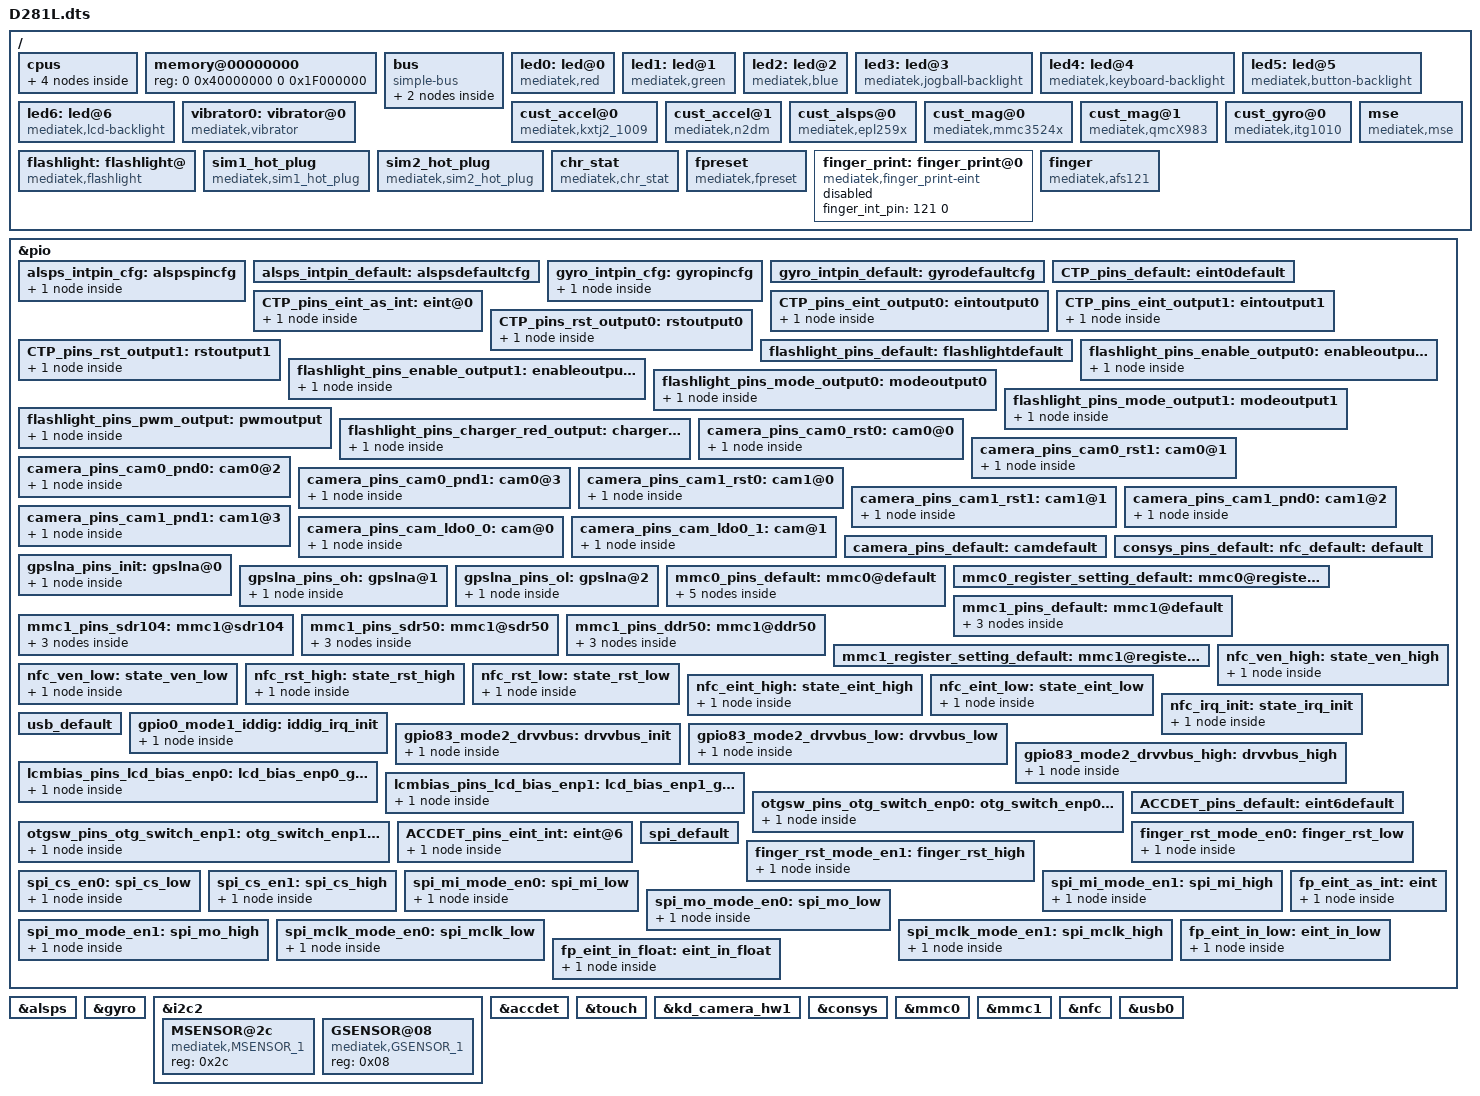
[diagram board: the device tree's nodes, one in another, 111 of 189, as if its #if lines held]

/dts-v1/;

#include "mt6735m.dtsi"
#include <dt-bindings/lcm/otm9608_qhd_dsi_cmd.dtsi>

/ {
	cpus {	#address-cells = <1>;
		#size-cells = <0>;

		cpu0: cpu@000 {
			device_type = "cpu";
			compatible = "arm,cortex-a53";
			reg = <0x000>;
			enable-method = "mt-boot";
			cpu-idle-states = <&cluster_sleep_0 &cluster_sleep_0 &cpu_sleep_0_0 &cpu_sleep_0_0>;
			cpu-release-addr = <0x0 0x40000200>;
			clock-frequency = <1100000000>;
		};

		cpu1: cpu@001 {
			device_type = "cpu";
			compatible = "arm,cortex-a53";
			reg = <0x001>;
			enable-method = "mt-boot";
			cpu-idle-states = <&cluster_sleep_0 &cluster_sleep_0 &cpu_sleep_0_0 &cpu_sleep_0_0>;
			cpu-release-addr = <0x0 0x40000200>;
			clock-frequency = <1100000000>;
		};

		cpu2: cpu@002 {
			device_type = "cpu";
			compatible = "arm,cortex-a53";
			reg = <0x002>;
			enable-method = "mt-boot";
			cpu-idle-states = <&cluster_sleep_0 &cluster_sleep_0 &cpu_sleep_0_0 &cpu_sleep_0_0>;
			cpu-release-addr = <0x0 0x40000200>;
			clock-frequency = <1100000000>;
		};

		cpu3: cpu@003 {
			device_type = "cpu";
			compatible = "arm,cortex-a53";
			reg = <0x003>;
			enable-method = "mt-boot";
			cpu-idle-states = <&cluster_sleep_0 &cluster_sleep_0 &cpu_sleep_0_0 &cpu_sleep_0_0>;
			cpu-release-addr = <0x0 0x40000200>;
			clock-frequency = <1100000000>;
		};
	};
	
	memory@00000000 {
		device_type = "memory";
		reg = <0 0x40000000 0 0x1F000000>;
	};

	bus {
		compatible = "simple-bus";
		#address-cells = <1>;
		#size-cells = <1>;
		ranges = <0 0 0 0xffffffff>;

		MALI@0x13040000 {
			compatible = "arm,malit720", "arm,mali-t72x", "arm,malit7xx", "arm,mali-midgard";
			reg = <0x13040000 0x4000>;
			interrupts = <0 212 0x8>, <0 211 0x8>, <0 210 0x8>;
			interrupt-names = "JOB", "MMU", "GPU";
			clock-frequency = <550000000>;
		};

		MTKFB@5e200000 {
			compatible = "mediatek,MTKFB";
			reg = <0x7F000000 0x1000000>;
		};

	};
//ranyanhao@wind-mobi.com 20160221 begin
	led0:led@0 {
		compatible = "mediatek,red";
		led_mode = <3>;
		data = <1>;
		pwm_config = <0 0 0 0 0>;
	};
	led1:led@1 {
		compatible = "mediatek,green";
		led_mode = <3>;
		data = <2>;
		pwm_config = <0 0 0 0 0>;
	};
//ranyanhao@wind-mobi.com 20160221 end
	led2:led@2 {
		compatible = "mediatek,blue";
		led_mode = <0>;
		data = <1>;
		pwm_config = <0 0 0 0 0>;
	};
	led3:led@3 {
		compatible = "mediatek,jogball-backlight";
		led_mode = <0>;
		data = <1>;
		pwm_config = <0 0 0 0 0>;
	};
	led4:led@4 {
		compatible = "mediatek,keyboard-backlight";
		led_mode = <0>;
		data = <1>;
		pwm_config = <0 0 0 0 0>;
	};
	led5:led@5 {
		compatible = "mediatek,button-backlight";
		led_mode = <0>;
		data = <1>;
		pwm_config = <0 0 0 0 0>;
	};
	led6:led@6 {
		compatible = "mediatek,lcd-backlight";
		led_mode = <5>;
		data = <1>;
		pwm_config = <0 0 0 0 0>;
	};
	vibrator0:vibrator@0 {
		compatible = "mediatek,vibrator";
		vib_timer = <25>;
		vib_limit = <9>;
//ranyanhao@wind-mobi.com 20160120 begin
		vib_vol= <6>;
//ranyanhao@wind-mobi.com 20160120 end
	};
 /* sensor standardization */
		cust_accel@0 {
/*huangzhaosong@wind-mobi.com 20151231 s---*/
		compatible = "mediatek,kxtj2_1009";
		i2c_num	= <2>;
		i2c_addr = <0x0e 0 0 0>;
		direction = <5>;
		power_id = <0xffff>;
		power_vol = <0>;
		firlen = <0>;
		is_batch_supported = <0>;
/*huangzhaosong@wind-mobi.com 20151231 e---*/
		};
/*hebiao@wind-mobi.com  20151230 begin*/
		cust_accel@1 {
		compatible = "mediatek,n2dm";
		i2c_num	= <2>;
		i2c_addr = <0x08 0 0 0>;
		direction = <5>;
		power_id = <0xffff>;
		power_vol = <0>;
		firlen = <6>;
		is_batch_supported = <0>;
		};
/*hebiao@wind-mobi.com  20151230 end*/

		cust_alsps@0 {
/*ranyanhao@wind-mobi.com  20151230 begin*/
		compatible = "mediatek,epl259x";
		i2c_num	= <2>;
		i2c_addr = <0x49 0 0 0>;
		polling_mode_ps = <0>;
		polling_mode_als = <1>;
		power_id = <0xffff>;
		power_vol = <0>;
		als_level = <30 160 260 605 1010 1380 1760 2100 2600 4000 5500 7000 9000 15000 20000>; /*modified by hebiao 2016413*/
		als_value = <0 50 100 260 400 520 700 850 1050 1550 3000 5000 7000 9000 20000 20000>;/*modified by hebiao 2016413*/
		ps_threshold_high		=  <800>;
		ps_threshold_low		=  <500>;
		is_batch_supported_ps	= <0>;
		is_batch_supported_als	= <0>;
/*ranyanhao@wind-mobi.com  20151230 end*/
		};
		
/*ranyanhao@wind-mobi.com  20160120 begin*/
		cust_mag@0 {
		compatible				= "mediatek,mmc3524x";
		i2c_num					= <2>;
		i2c_addr				= <0x30 0 0 0>;
		direction				= <7>;
		power_id				= <0xffff>;
		power_vol				= <0>;
		is_batch_supported			= <0>;
		};
/*ranyanhao@wind-mobi.com  20160120 end*/

/*hebiao@wind-mobi.com  20160324 begin*/
cust_mag@1 {
		compatible				= "mediatek,qmcX983";
		i2c_num					= <2>;
		i2c_addr				= <0x2c 0 0 0>;
		/*modified by lifengxiang@wind-mobi.com 20160628 begin*/
		direction				= <4>;
		/*modified by lifengxiang@wind-mobi.com 20160628 end*/
		power_id				= <0xffff>;
		power_vol				= <0>;
		is_batch_supported			= <0>;
		}; 
/*hebiao@wind-mobi.com  20160324 end*/

		cust_gyro@0 {
		compatible				= "mediatek,itg1010";
		i2c_num					= <2>;
		i2c_addr				= <0x68 0 0 0>;
		direction				= <3>;
		power_id				= <0xffff>;
		power_vol				= <0>;
		firlen					= <0>;
		is_batch_supported			= <0>;
		};

/*hebiao@wind-mobi.com 20160219 begin*/
		flashlight: flashlight@ {
	 			compatible = "mediatek,flashlight";
		};
/*hebiao@wind-mobi.com 20160219 end*/
		
/* ranyanhao@wind-mobi.com 20160121 begin */
		sim1_hot_plug: sim1_hot_plug {
			compatible = "mediatek,sim1_hot_plug";
		};
		
		sim2_hot_plug: sim2_hot_plug {
			compatible = "mediatek,sim2_hot_plug";
		};
		
		mse: mse {
			compatible = "mediatek,mse";
		};
		
		chr_stat: chr_stat {
			compatible = "mediatek,chr_stat";
		};
/* ranyanhao@wind-mobi.com 20160121 end */

/*liukangping@wind-mobi.com 20160421 begin  */
fpreset: fpreset{
    compatible = "mediatek,fpreset";
	pinctrl-names =  "spi_default", "finger_rst_low", "finger_rst_high";
	pinctrl-0 = <&spi_default>;
	pinctrl-1 = <&finger_rst_mode_en0>;
	pinctrl-2 = <&finger_rst_mode_en1>;
	status = "okay";
};
/*liukangping@wind-mobi.com 20160421 end  */

/*****zhenglihong@wind-mobi.com 20160430 begin*********/		
/*ranyanhao@wind-mobi.com 20160229 begin*/
		finger_print: finger_print@0 {
			compatible = "mediatek,finger_print-eint";
		/*dingyisheng@wind-mobi.com 20170317 begin  */
			finger_int_pin = <121 0>;
		/*dingyisheng@wind-mobi.com 20170317 end  */
			status = "disabled";
		};
		finger:finger {
			compatible = "mediatek,afs121";
				pinctrl-names = "spi_default","spi_cs_low","spi_cs_high","spi_mi_low","spi_mi_high",
					"spi_mo_low","spi_mo_high","spi_mclk_low","spi_mclk_high",
					"finger_rst_low","finger_rst_high",
					"eint","eint_in_low","eint_in_float";
			pinctrl-0 = <&spi_default>;
			pinctrl-1 = <&spi_cs_en0>;
			pinctrl-2 = <&spi_cs_en1>;
			pinctrl-3 = <&spi_mi_mode_en0>;
			pinctrl-4 = <&spi_mi_mode_en1>;
			pinctrl-5 = <&spi_mo_mode_en0>;
			pinctrl-6 = <&spi_mo_mode_en1>;
			pinctrl-7 = <&spi_mclk_mode_en0>;
			pinctrl-8 = <&spi_mclk_mode_en1>;
			pinctrl-9 = <&finger_rst_mode_en0>;
			pinctrl-10 = <&finger_rst_mode_en1>;
			pinctrl-11 = <&fp_eint_as_int>;
			pinctrl-12 = <&fp_eint_in_low>;
			pinctrl-13 = <&fp_eint_in_float>;
			status = "okay";
		};
/*ranyanhao@wind-mobi.com 20160229 end*/
};
/******zhenglihong@wind-mobi.com 20160430 end***********************/

/* sensor gpio standization */
&pio {
	alsps_intpin_cfg: alspspincfg {

	    pins_cmd_dat {
		/*ranyanhao@wind-mobi.com 20160120 begin*/
			pins = <PINMUX_GPIO77__FUNC_GPIO77>;
		/*ranyanhao@wind-mobi.com 20160120 end*/
			slew-rate = <0>;
			bias-pull-up = <00>;
		};
	};

	alsps_intpin_default: alspsdefaultcfg {

	};

	gyro_intpin_cfg: gyropincfg {

	    pins_cmd_dat {
			pins = <PINMUX_GPIO67__FUNC_GPIO67>;
			slew-rate = <0>;
			bias-pull-down = <00>;
		};
	};

	gyro_intpin_default: gyrodefaultcfg {

	};
};
&alsps {
	pinctrl-names = "pin_default", "pin_cfg";
	pinctrl-0 = <&alsps_intpin_default>;
	pinctrl-1 = <&alsps_intpin_cfg>;
	status = "okay";

};

&gyro {
	pinctrl-names = "pin_default", "pin_cfg";
	pinctrl-0 = <&gyro_intpin_default>;
	pinctrl-1 = <&gyro_intpin_cfg>;
	status = "okay";

};
/* sensor end */

/* i2c reuse begin */
/* hebiao@wind-mobi.com 20160315 begin */
&i2c2 {
	MSENSOR@2c {
		compatible = "mediatek,MSENSOR_1";
		reg = <0x2c>;
	};
	};

&i2c2 {
	GSENSOR@08 {
		compatible = "mediatek,GSENSOR_1";
		reg = <0x08>;
	};
	};
/* hebiao@wind-mobi.com 20160315 end */
/* i2c reuse end */

/* ranyanhao@wind-mobi.com 20160120 begin */
&accdet {
	accdet-mic-vol = <7>;
	headset-mode-setting = <0x500 0x200 1 0x1F0 0x800 0x800 0x20>;
	accdet-plugout-debounce = <20>;
	/*1:ACC mode, 2:low cost without in bias, 6:low cost with in bias*/
	accdet-mic-mode = <1>;
	/*0--MD_MAX--UP_MAX--DW_MAX*/
	headset-three-key-threshold = <0 80 220 500>;
	/*0--MD_MAX--VOICE_MAX--UP_MAX--DW_MAX*/
	headset-four-key-threshold = <0 58 121 192 450>;
	pinctrl-names = "default", "state_eint_as_int";
	pinctrl-0 = <&ACCDET_pins_default>;
	pinctrl-1 = <&ACCDET_pins_eint_int>;
	status = "okay";
};
/* ranyanhao@wind-mobi.com 20160120 end */
&touch {
	tpd-resolution = <720 1280>;
	use-tpd-button = <0>;
	tpd-key-num = <3>;
	tpd-key-local= <139 172 158 0>;
	tpd-key-dim-local = <90 883 100 40 230 883 100 40 370 883 100 40 0 0 0 0>;
	tpd-max-touch-num = <5>;
	tpd-filter-enable = <1>;
	tpd-filter-pixel-density = <124>;
	tpd-filter-custom-prameters = <0 0 0 0 0 0 0 0 0 0 0 0>;
	tpd-filter-custom-speed = <0 0 0>;
	pinctrl-names = "default", "state_eint_as_int", "state_eint_output0", "state_eint_output1",
		"state_rst_output0", "state_rst_output1";
	pinctrl-0 = <&CTP_pins_default>;
	pinctrl-1 = <&CTP_pins_eint_as_int>;
	pinctrl-2 = <&CTP_pins_eint_output0>;
	pinctrl-3 = <&CTP_pins_eint_output1>;
	pinctrl-4 = <&CTP_pins_rst_output0>;
	pinctrl-5 = <&CTP_pins_rst_output1>;
	status = "okay";
};
&pio {
	CTP_pins_default: eint0default {
	};
	CTP_pins_eint_as_int: eint@0 {
		pins_cmd_dat {
			pins = <PINMUX_GPIO10__FUNC_GPIO10>;
			slew-rate = <0>;
			bias-pull-up = <00>;  /*pull up int  modified by hebiao*/
			/*bias-disable;*/
		};
	};
	CTP_pins_eint_output0: eintoutput0 {
		pins_cmd_dat {
			pins = <PINMUX_GPIO10__FUNC_GPIO10>;
			slew-rate = <1>;
			output-low;
		};
	};
	CTP_pins_eint_output1: eintoutput1 {
		pins_cmd_dat {
			pins = <PINMUX_GPIO10__FUNC_GPIO10>;
			slew-rate = <1>;
			output-high;
		};
	};
	CTP_pins_rst_output0: rstoutput0 {
		pins_cmd_dat {
			pins = <PINMUX_GPIO62__FUNC_GPIO62>;
			slew-rate = <1>;
			output-low;
		};
	};
	CTP_pins_rst_output1: rstoutput1 {
		pins_cmd_dat {
			pins = <PINMUX_GPIO62__FUNC_GPIO62>;
			slew-rate = <1>;
			output-high;
		};
	};
};
/* TOUCH end */

/* hebiao@wind-mobi.com 20160219 begin */
&flashlight {
	pinctrl-names =  "default", "state_enable_output0", "state_enable_output1",
		"state_mode_output0", "state_mode_output1", "state_pwm_output", "charger_red_GPIO_output";
	pinctrl-0 = <&flashlight_pins_default>;
	pinctrl-1 = <&flashlight_pins_enable_output0>;
	pinctrl-2 = <&flashlight_pins_enable_output1>;
	pinctrl-3 = <&flashlight_pins_mode_output0>;
	pinctrl-4 = <&flashlight_pins_mode_output1>;
	pinctrl-5 = <&flashlight_pins_pwm_output>;
	pinctrl-6 = <&flashlight_pins_charger_red_output>;
	status = "okay";
};

&pio {
	flashlight_pins_default: flashlightdefault {
	};
	flashlight_pins_enable_output0: enableoutput0 {
		pins_cmd_dat {
			pins = <PINMUX_GPIO42__FUNC_GPIO42>;
			slew-rate = <1>;
			output-low;
		};
	};
	flashlight_pins_enable_output1: enableoutput1 {
		pins_cmd_dat {
			pins = <PINMUX_GPIO42__FUNC_GPIO42>;
			slew-rate = <1>;
			output-high;
		};
	};
	flashlight_pins_mode_output0: modeoutput0 {
		pins_cmd_dat {
			pins = <PINMUX_GPIO1__FUNC_GPIO1>;
			slew-rate = <1>;
			output-low;
		};
	};
	flashlight_pins_mode_output1: modeoutput1 {
		pins_cmd_dat {
			pins = <PINMUX_GPIO1__FUNC_GPIO1>;
			slew-rate = <1>;
			output-high;	
		};
	};
	flashlight_pins_pwm_output: pwmoutput {
		pins_cmd_dat {
			pins = <PINMUX_GPIO1__FUNC_PWM2>;
			slew-rate = <1>;
		};
	};
	flashlight_pins_charger_red_output: charger_red_GPIO_output { 
		pins_cmd_dat {
			pins = <PINMUX_GPIO57__FUNC_GPIO57>;
			slew-rate = <1>;
			output-high;
		};
	};
};
/* hebiao@wind-mobi.com 20160219 end */

/* ranyanhao@wind-mobi.com 20160121 begin */
&sim1_hot_plug {
	status = "okay";
};

&sim2_hot_plug {
	status = "okay";
};

&mse {
	status = "okay";
};

&chr_stat {
	status = "okay";
};
/* ranyanhao@wind-mobi.com 20160121 end */

/* CAMERA GPIO standardization */
&pio {
	camera_pins_cam0_rst0: cam0@0 {
	    pins_cmd_dat {
			pins = <PINMUX_GPIO44__FUNC_GPIO44>;/*GPIO_CAMERA_CMRST_PIN*/
			slew-rate = <1>; /*direction 0:in, 1:out*/
			output-low;/*direction out used only. output_low or high*/
		};
	};
	camera_pins_cam0_rst1: cam0@1 {
	    pins_cmd_dat {
			pins = <PINMUX_GPIO44__FUNC_GPIO44>;/*GPIO_CAMERA_CMRST_PIN*/
			slew-rate = <1>;
			output-high;
		};
	};
	camera_pins_cam0_pnd0: cam0@2 {
	    pins_cmd_dat {
			pins = <PINMUX_GPIO7__FUNC_GPIO7>;/*GPIO_CAMERA_CMPDN_PIN*/
			slew-rate = <1>;
			output-low;
		};
	};
	camera_pins_cam0_pnd1: cam0@3 {
	    pins_cmd_dat {
			pins = <PINMUX_GPIO7__FUNC_GPIO7>;/*GPIO_CAMERA_CMPDN_PIN*/
			slew-rate = <1>;
			output-high;
		};
	};
	camera_pins_cam1_rst0: cam1@0 {
	    pins_cmd_dat {
			pins = <PINMUX_GPIO11__FUNC_GPIO11>;/*GPIO_CAMERA_CMRST1_PIN*/
			slew-rate = <1>; /*direction 0:in, 1:out*/
			output-low;/*direction out used only. output_low or high*/
		};
	};
	camera_pins_cam1_rst1: cam1@1 {
	    pins_cmd_dat {
			pins = <PINMUX_GPIO11__FUNC_GPIO11>;/*GPIO_CAMERA_CMRST1_PIN*/
			slew-rate = <1>;
			output-high;
		};
	};
	camera_pins_cam1_pnd0: cam1@2 {
	    pins_cmd_dat {
			pins = <PINMUX_GPIO12__FUNC_GPIO12>;/*GPIO_CAMERA_CMPDN1_PIN*/
			slew-rate = <1>;
			output-low;
		};
	};
	camera_pins_cam1_pnd1: cam1@3 {
	    pins_cmd_dat {
			pins = <PINMUX_GPIO12__FUNC_GPIO12>;/*GPIO_CAMERA_CMPDN1_PIN*/
			slew-rate = <1>;
			output-high;
		};
	};
	camera_pins_cam_ldo0_0: cam@0 {
	    pins_cmd_dat {
			pins = <PINMUX_GPIO68__FUNC_GPIO68>;/*GPIO_SPI_MOSI_PIN*/
			slew-rate = <1>;
			output-low;
		};
	};
	camera_pins_cam_ldo0_1: cam@1 {
		pins_cmd_dat {
			pins = <PINMUX_GPIO68__FUNC_GPIO68>;/*GPIO_SPI_MOSI_PIN*/
			slew-rate = <1>;
			output-high;
		};
	};
	camera_pins_default: camdefault {
	};

};

&kd_camera_hw1 {
	pinctrl-names = "default", "cam0_rst0", "cam0_rst1", "cam0_pnd0", "cam0_pnd1",
			"cam1_rst0", "cam1_rst1", "cam1_pnd0", "cam1_pnd1","cam_ldo0_0", "cam_ldo0_1";
	pinctrl-0 = <&camera_pins_default>;
	pinctrl-1 = <&camera_pins_cam0_rst0>;
	pinctrl-2 = <&camera_pins_cam0_rst1>;
	pinctrl-3 = <&camera_pins_cam0_pnd0>;
	pinctrl-4 = <&camera_pins_cam0_pnd1>;
	pinctrl-5 = <&camera_pins_cam1_rst0>;
	pinctrl-6 = <&camera_pins_cam1_rst1>;
	pinctrl-7 = <&camera_pins_cam1_pnd0>;
	pinctrl-8 = <&camera_pins_cam1_pnd1>;
	pinctrl-9 = <&camera_pins_cam_ldo0_0>;
	pinctrl-10 = <&camera_pins_cam_ldo0_1>;
	status = "okay";

};
/* CAMERA GPIO end */

/* CONSYS GPIO standardization */
&pio {
	consys_pins_default: default {

	};

	gpslna_pins_init: gpslna@0 {

	    pins_cmd_dat {
			pins = <PINMUX_GPIO79__FUNC_GPIO79>;
			slew-rate = <0>;
			bias-disable;
			output-low;
		};
	};

	gpslna_pins_oh: gpslna@1 {

	    pins_cmd_dat {
			pins = <PINMUX_GPIO79__FUNC_GPIO79>;
			slew-rate = <1>;
			output-high;
		};
	};

	gpslna_pins_ol: gpslna@2 {

	    pins_cmd_dat {
			pins = <PINMUX_GPIO79__FUNC_GPIO79>;
			slew-rate = <1>;
			output-low;
		};
	};

};

&consys {
	pinctrl-names = "default", "gps_lna_state_init", "gps_lna_state_oh", "gps_lna_state_ol";
	pinctrl-0 = <&consys_pins_default>;
	pinctrl-1 = <&gpslna_pins_init>;
	pinctrl-2 = <&gpslna_pins_oh>;
	pinctrl-3 = <&gpslna_pins_ol>;
	status = "okay";

};
/* CONSYS end */

/* mmc start */
&mmc0 {
		clk_src = /bits/ 8 <MSDC50_CLKSRC_400MHZ>;
		bus-width = <8>;
		max-frequency = <200000000>;
		cap-mmc-highspeed;
		msdc-sys-suspend;
		mmc-ddr-1_8v;
		mmc-hs200-1_8v;
		mmc-hs400-1_8v;
		non-removable;
		pinctl = <&mmc0_pins_default>;
		register_setting = <&mmc0_register_setting_default>;
		host_function = /bits/ 8 <MSDC_EMMC>;
		bootable;
		status = "okay";
};

&mmc1 {
		clk_src = /bits/ 8 <MSDC30_CLKSRC_200MHZ>;
		bus-width = <4>;
		max-frequency = <200000000>;
		msdc-sys-suspend;
		cap-sd-highspeed;
		sd-uhs-sdr12;
		sd-uhs-sdr25;
		sd-uhs-sdr50;
		sd-uhs-sdr104;
		sd-uhs-ddr50;
		pinctl = <&mmc1_pins_default>;
		pinctl_sdr104 = <&mmc1_pins_sdr104>;
		pinctl_sdr50 = <&mmc1_pins_sdr50>;
		pinctl_ddr50 = <&mmc1_pins_ddr50>;
		register_setting = <&mmc1_register_setting_default>;
		host_function = /bits/ 8 <MSDC_SD>;
		cd_level = /bits/ 8 <MSDC_CD_LOW>;
		cd-gpios = <&pio 5 0>;
		status = "okay";
};

&pio {
	mmc0_pins_default: mmc0@default {
			pins_cmd {
				drive-strength = /bits/ 8 <2>;
			};
			pins_dat {
				drive-strength = /bits/ 8 <2>;
			};
			pins_clk {
				drive-strength = /bits/ 8 <2>;
			};
			pins_rst {
				drive-strength = /bits/ 8 <2>;
			};
			pins_ds {
				drive-strength = /bits/ 8 <2>;
			};
	};

	mmc0_register_setting_default: mmc0@register_default {
		dat0rddly      = /bits/ 8 <0>;
		dat1rddly      = /bits/ 8 <0>;
		dat2rddly      = /bits/ 8 <0>;
		dat3rddly      = /bits/ 8 <0>;
		dat4rddly      = /bits/ 8 <0>;
		dat5rddly      = /bits/ 8 <0>;
		dat6rddly      = /bits/ 8 <0>;
		dat7rddly      = /bits/ 8 <0>;
		datwrddly      = /bits/ 8 <0>;
		cmdrrddly      = /bits/ 8 <0>;
		cmdrddly       = /bits/ 8 <0>;
		cmd_edge = /bits/ 8 <MSDC_SMPL_FALLING>;
		rdata_edge = /bits/ 8 <MSDC_SMPL_FALLING>;
		wdata_edge = /bits/ 8 <MSDC_SMPL_FALLING>;

		ett-hs200-cells = <12>;
		ett-hs200-default = <OFFSET_MSDC_PATCH_BIT0	MSDC_PB0_INT_DAT_LATCH_CK_SEL 0x0
			OFFSET_MSDC_PATCH_BIT0	MSDC_PB0_CKGEN_MSDC_DLY_SEL   0x0
			OFFSET_MSDC_PATCH_BIT1	MSDC_PB1_CMD_RSP_TA_CNTR      0x1
			OFFSET_MSDC_IOCON		MSDC_IOCON_RSPL               0x0
			OFFSET_MSDC_PAD_TUNE0	MSDC_PAD_TUNE0_CMDRDLY        0x7
			OFFSET_MSDC_PAD_TUNE0	MSDC_PAD_TUNE0_CMDRRDLY       0xb
			OFFSET_MSDC_PATCH_BIT1		MSDC_PB1_WRDAT_CRCS_TA_CNTR   0x1
			OFFSET_MSDC_PAD_TUNE0	MSDC_PAD_TUNE0_DATWRDLY       0xb
			OFFSET_MSDC_IOCON			MSDC_IOCON_W_D0SPL            0x0
			OFFSET_MSDC_DAT_RDDLY0		MSDC_DAT_RDDLY0_D0            0x7
			OFFSET_MSDC_PAD_TUNE0	MSDC_PAD_TUNE0_DATRRDLY       0x9
			OFFSET_MSDC_IOCON		MSDC_IOCON_R_D_SMPL           0x0>;

		ett-hs400-cells = <8>;
		ett-hs400-default = <OFFSET_MSDC_PATCH_BIT0	MSDC_PB0_INT_DAT_LATCH_CK_SEL	0x0
			OFFSET_MSDC_PATCH_BIT0		MSDC_PB0_CKGEN_MSDC_DLY_SEL		0x0
			OFFSET_EMMC50_PAD_DS_TUNE	MSDC_EMMC50_PAD_DS_TUNE_DLY1	0x2
			OFFSET_EMMC50_PAD_DS_TUNE	MSDC_EMMC50_PAD_DS_TUNE_DLY3	0x10
			OFFSET_MSDC_PATCH_BIT1			MSDC_PB1_CMD_RSP_TA_CNTR	0x1
			OFFSET_MSDC_IOCON		MSDC_IOCON_RSPL				0x0
			OFFSET_MSDC_PAD_TUNE0			MSDC_PAD_TUNE0_CMDRDLY		0x6
			OFFSET_MSDC_PAD_TUNE0		MSDC_PAD_TUNE0_CMDRRDLY		0x6>;
	};

	mmc1_pins_default: mmc1@default {
			pins_cmd {
				drive-strength = /bits/ 8 <3>;
			};
			pins_dat {
				drive-strength = /bits/ 8 <3>;
			};
			pins_clk {
				drive-strength = /bits/ 8 <3>;
			};
	};

	mmc1_pins_sdr104: mmc1@sdr104 {
			pins_cmd {
				drive-strength = /bits/ 8 <2>;
			};
			pins_dat {
				drive-strength = /bits/ 8 <2>;
			};
			pins_clk {
				drive-strength = /bits/ 8 <3>;
			};
	};

	mmc1_pins_sdr50: mmc1@sdr50 {
			pins_cmd {
				drive-strength = /bits/ 8 <2>;
			};
			pins_dat {
				drive-strength = /bits/ 8 <2>;
			};
			pins_clk {
				drive-strength = /bits/ 8 <3>;
			};
	};

	mmc1_pins_ddr50: mmc1@ddr50 {
			pins_cmd {
				drive-strength = /bits/ 8 <2>;
			};
			pins_dat {
				drive-strength = /bits/ 8 <2>;
			};
			pins_clk {
				drive-strength = /bits/ 8 <3>;
			};
	};

	mmc1_register_setting_default: mmc1@register_default {
				dat0rddly      = /bits/ 8 <0>;
				dat1rddly      = /bits/ 8 <0>;
				dat2rddly      = /bits/ 8 <0>;
				dat3rddly      = /bits/ 8 <0>;
				datwrddly      = /bits/ 8 <0>;
				cmdrrddly      = /bits/ 8 <0>;
				cmdrddly       = /bits/ 8 <0>;
				cmd_edge = /bits/ 8 <MSDC_SMPL_FALLING>;
				rdata_edge = /bits/ 8 <MSDC_SMPL_FALLING>;
				wdata_edge = /bits/ 8 <MSDC_SMPL_FALLING>;
	};
};
/* mmc end */

/* NFC GPIO standardization */
&pio {
	nfc_default: default {

	};

	nfc_ven_high: state_ven_high {
		pins_cmd_dat {
			pins = <PINMUX_GPIO4__FUNC_GPIO4>;
			slew-rate = <1>;
			output-high;
		};
	};

	nfc_ven_low: state_ven_low {
		pins_cmd_dat {
			pins = <PINMUX_GPIO4__FUNC_GPIO4>;
			slew-rate = <1>;
			output-low;
		};
	};

	nfc_rst_high: state_rst_high {
		pins_cmd_dat {
			pins = <PINMUX_GPIO3__FUNC_GPIO3>;
			slew-rate = <1>;
			output-high;
		};
	};

	nfc_rst_low: state_rst_low {
		pins_cmd_dat {
			pins = <PINMUX_GPIO3__FUNC_GPIO3>;
			slew-rate = <1>;
			output-low;
		};
	};

	nfc_eint_high: state_eint_high {
		pins_cmd_dat {
			pins = <PINMUX_GPIO1__FUNC_GPIO1>;
			slew-rate = <1>;
			output-high;
		};
	};

	nfc_eint_low: state_eint_low {
		pins_cmd_dat {
			pins = <PINMUX_GPIO1__FUNC_GPIO1>;
			slew-rate = <1>;
			output-low;
		};
	};

	nfc_irq_init: state_irq_init {
		pins_cmd_dat {
			pins = <PINMUX_GPIO2__FUNC_GPIO2>;
			slew-rate = <0>;
			bias-pull-down = <00>;
		};
	};
};

&nfc {
	pinctrl-names = "default", "ven_high", "ven_low", "rst_high", "rst_low", "eint_high", "eint_low", "irq_init";
	pinctrl-0 = <&nfc_default>;
	pinctrl-1 = <&nfc_ven_high>;
	pinctrl-2 = <&nfc_ven_low>;
	pinctrl-3 = <&nfc_rst_high>;
	pinctrl-4 = <&nfc_rst_low>;
	pinctrl-5 = <&nfc_eint_high>;
	pinctrl-6 = <&nfc_eint_low>;
	pinctrl-7 = <&nfc_irq_init>;
	status = "okay";
};
/* NFC end */

/* USB GPIO Kernal Standardization start */
&pio {
	usb_default: usb_default {
	};

	gpio0_mode1_iddig: iddig_irq_init {
		pins_cmd_dat {
			pins = <PINMUX_GPIO0__FUNC_IDDIG>;
			slew-rate = <0>;
			bias-pull-up = <00>;
		};
	};

	gpio83_mode2_drvvbus: drvvbus_init {
		pins_cmd_dat {
			pins = <PINMUX_GPIO83__FUNC_GPIO83>;
			slew-rate = <1>;
			bias-pull-down = <00>;
		};
	};

	gpio83_mode2_drvvbus_low: drvvbus_low {
		pins_cmd_dat {
			pins = <PINMUX_GPIO83__FUNC_GPIO83>;
			slew-rate = <1>;
			output-low;
			bias-pull-down = <00>;
		};
	};

	gpio83_mode2_drvvbus_high: drvvbus_high {
		pins_cmd_dat {
			pins = <PINMUX_GPIO83__FUNC_GPIO83>;
			slew-rate = <1>;
			output-high;
			bias-pull-down = <00>;
		};
	};
};

&usb0 {
	iddig_gpio = <0 1>;
	pinctrl-names = "usb_default", "iddig_irq_init", "drvvbus_init", "drvvbus_low", "drvvbus_high";
	pinctrl-0 = <&usb_default>;
	pinctrl-1 = <&gpio0_mode1_iddig>;
	pinctrl-2 = <&gpio83_mode2_drvvbus>;
	pinctrl-3 = <&gpio83_mode2_drvvbus_low>;
	pinctrl-4 = <&gpio83_mode2_drvvbus_high>;
	status = "okay";
};
/* USB GPIO Kernal Standardization end */

/* zhaozhensen@wind-mobi.com 20160423 begin*/
&pio {

	lcmbias_pins_default: default {
	};

	lcmbias_pins_lcd_bias_enp0: lcd_bias_enp0_gpio {
		pins_cmd_dat {
			pins = <PINMUX_GPIO119__FUNC_GPIO119>;
			slew-rate = <1>;
			output-low;
		};
	};

	lcmbias_pins_lcd_bias_enp1: lcd_bias_enp1_gpio {
		pins_cmd_dat {
			pins = <PINMUX_GPIO119__FUNC_GPIO119>;
			slew-rate = <1>;
			output-high;
		};
	};

};

/* zhaozhensen@wind-mobi.com 20160423 end*/

/* yutao@wind-mobi.com 20160601 begin*/
&pio {

	otgsw_pins_default: default {
	};

	otgsw_pins_otg_switch_enp0: otg_switch_enp0_gpio {
		pins_cmd_dat {
			pins = <PINMUX_GPIO3__FUNC_GPIO3>;
			slew-rate = <1>;
			output-low;
		};
	};

	otgsw_pins_otg_switch_enp1: otg_switch_enp1_gpio {
		pins_cmd_dat {
			pins = <PINMUX_GPIO3__FUNC_GPIO3>;
			slew-rate = <1>;
			output-high;
		};
	};

};

/* yutao@wind-mobi.com 20160601 end*/

/* ranyanhao@wind-mobi.com 20160120 begin */
/* ACCDET GPIO Standardization ACC mode use */
&pio {
	ACCDET_pins_default:eint6default {
	};
	ACCDET_pins_eint_int:eint@6 {
		pins_cmd_dat {
			pins = <PINMUX_GPIO6__FUNC_GPIO6>;
			slew-rate = <0>;
			bias-disable;
		};
	};
};
/* ACCDET END */
/* ranyanhao@wind-mobi.com 20160120 end */

/*liukangping@wind-mobi.com 20160421 begin */		
&pio {
	spi_default: spi_default {
	};
	
	finger_rst_mode_en0: finger_rst_low {
		pins_cmd_dat {
			pins = <PINMUX_GPIO122__FUNC_GPIO122>;
			slew-rate = <1>;
			output-low;
		};
	};
	finger_rst_mode_en1: finger_rst_high {
		pins_cmd_dat {
			pins = <PINMUX_GPIO122__FUNC_GPIO122>;
			slew-rate = <1>;
			output-high;
		};
	};	
	
};
/*liukangping@wind-mobi.com 20160421 end */
/* ranyanhao@wind-mobi.com 20160120 begin */
&pio {
	spi_default: spi_default {
	};

	spi_cs_en0: spi_cs_low {
		pins_cmd_dat {
			pins = <PINMUX_GPIO65__FUNC_SPI_CSA>;
			slew-rate = <1>;
			output-low;
		};
	};
	spi_cs_en1: spi_cs_high {
		pins_cmd_dat {
			pins = <PINMUX_GPIO65__FUNC_SPI_CSA>;
			slew-rate = <1>;
			output-high;
		};
	};	
	spi_mi_mode_en0: spi_mi_low {
		pins_cmd_dat {
			pins = <PINMUX_GPIO67__FUNC_SPI_MIA>;
			slew-rate = <0>;
			bias-pull-up = <00>;
		};
	};
	spi_mi_mode_en1: spi_mi_high {
		pins_cmd_dat {
			pins = <PINMUX_GPIO67__FUNC_SPI_MIA>;
			bias-disable;
		};
	};	
	spi_mo_mode_en0: spi_mo_low {
		pins_cmd_dat {
			pins = <PINMUX_GPIO68__FUNC_SPI_MOA>;
			slew-rate = <1>;
			output-low;
		};
	};
	spi_mo_mode_en1: spi_mo_high {
		pins_cmd_dat {
			pins = <PINMUX_GPIO68__FUNC_SPI_MOA>;
			slew-rate = <1>;
			output-high;
		};
	};	
		spi_mclk_mode_en0: spi_mclk_low {
		pins_cmd_dat {
			pins = <PINMUX_GPIO66__FUNC_SPI_CKA>;
			slew-rate = <1>;
			output-low;
		};
	};
	spi_mclk_mode_en1: spi_mclk_high {
		pins_cmd_dat {
			pins = <PINMUX_GPIO66__FUNC_SPI_CKA>;
			slew-rate = <1>;
			output-high;
		};
	};	

	finger_rst_mode_en0: finger_rst_low {
		pins_cmd_dat {
			pins = <PINMUX_GPIO122__FUNC_GPIO122>;
			slew-rate = <1>;
			output-low;
		};
	};
	finger_rst_mode_en1: finger_rst_high {
		pins_cmd_dat {
			pins = <PINMUX_GPIO122__FUNC_GPIO122>;
			slew-rate = <1>;
			output-high;
		};
	};	
	
	fp_eint_as_int: eint {
		pins_cmd_dat {
			pins = <PINMUX_GPIO121__FUNC_GPIO121>;
			slew-rate = <0>;
			bias-disable;
		};
	};
	
	fp_eint_in_low: eint_in_low {
		pins_cmd_dat {
			pins = <PINMUX_GPIO121__FUNC_GPIO121>;
			slew-rate = <0>;
			bias-pull-down = <0>;
		};
	};
	
	fp_eint_in_float: eint_in_float {
		pins_cmd_dat {
			pins = <PINMUX_GPIO121__FUNC_GPIO121>;
			slew-rate = <0>;
			bias-disable;
		};
	};	
};

#include "cust.dtsi"
#include <generated/autoconf.h>
#ifdef CONFIG_MTK_HAFG_20
#include "D281L_fg20_bat_setting.dtsi"
#else
#include "D281L_fg_oldgauge_bat_setting.dtsi"
#endif
/* ranyanhao@wind-mobi.com 20160120 end */
